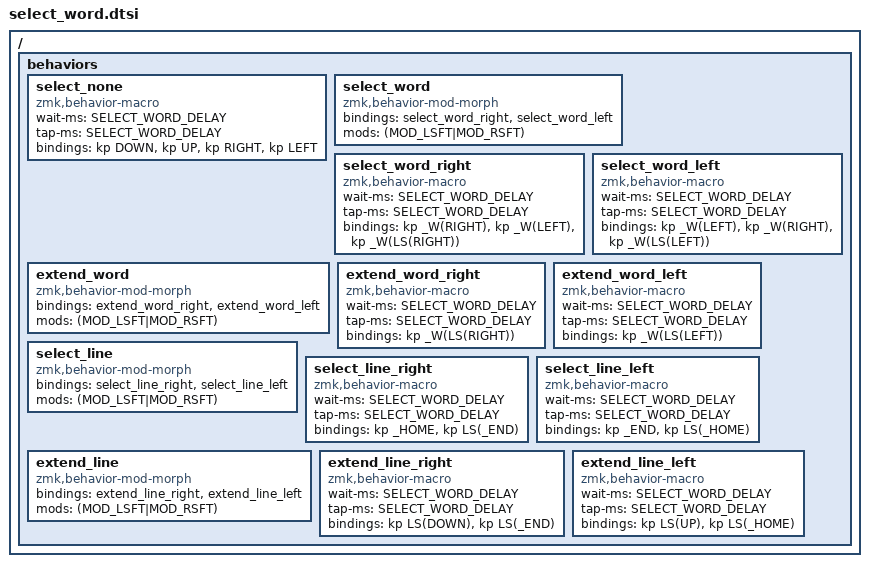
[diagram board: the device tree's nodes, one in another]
/* Original code copied from Sunaku's Keymap modified to use zmk-helpers - https://github.com/sunaku/glove80-keymaps */

/* Include helpers here as they are required for the behavior.

   NOTE: all usages of ZMK_ functions are overriden from this point on,
   so only include modules/functions working with them
*/
#include <zmk-helpers/helper.h>

/* Include the shortcuts.h if not included yet */
#ifndef _ZMK_KEYMAP_UTILS_SHORTCUTS_IMPORT
#include <zmk-keymap-utils/shortcuts.h>
#endif

//////////////////////////////////////////////////////////////////////////
//
// Approximation of Pascal Getreuer's Select Word macro from QMK
// - https://getreuer.info/posts/keyboards/select-word/index.html
//
//////////////////////////////////////////////////////////////////////////

//
// SELECT_WORD_DELAY defines how long the macro waits (milliseconds)
// after moving the cursor before it selects a word.  A larger delay
// may allow the macro to move to the next word upon each invocation.
//
#ifndef SELECT_WORD_DELAY
#define SELECT_WORD_DELAY 1
#endif

//////////////////////////////////////////////////////////////////////////
//
// Approximation of Pascal Getreuer's Select Word macro from QMK
// - https://getreuer.info/posts/keyboards/select-word/index.html
//
//////////////////////////////////////////////////////////////////////////

//
// SELECT_WORD_DELAY defines how long the macro waits (milliseconds)
// after moving the cursor before it selects a word.  A larger delay
// may allow the macro to move to the next word upon each invocation.
//
#ifndef SELECT_WORD_DELAY
#define SELECT_WORD_DELAY 1
#endif

// select all alias for shortcut
#define select_all kp _C(A)

ZMK_MACRO(select_none,
    wait-ms = <SELECT_WORD_DELAY>;
    tap-ms = <SELECT_WORD_DELAY>;
    bindings = <&kp DOWN &kp UP &kp RIGHT &kp LEFT>;
)

//
// select a word (jumps to next word upon each successive invocation)
//
ZMK_MOD_MORPH(select_word,
    bindings = <&select_word_right>, <&select_word_left>;
    mods = <(MOD_LSFT|MOD_RSFT)>;
)
ZMK_MACRO(select_word_right,
    wait-ms = <SELECT_WORD_DELAY>;
    tap-ms = <SELECT_WORD_DELAY>;
    bindings = <&kp _W(RIGHT) &kp _W(LEFT) &kp _W(LS(RIGHT))>;
)
ZMK_MACRO(select_word_left,
    wait-ms = <SELECT_WORD_DELAY>;
    tap-ms = <SELECT_WORD_DELAY>;
    bindings = <&kp _W(LEFT) &kp _W(RIGHT) &kp _W(LS(LEFT))>;
)
//
// extend current selection by one word
//
ZMK_MOD_MORPH(extend_word,
    bindings = <&extend_word_right>, <&extend_word_left>;
    mods = <(MOD_LSFT|MOD_RSFT)>;
)
ZMK_MACRO(extend_word_right,
    wait-ms = <SELECT_WORD_DELAY>;
    tap-ms = <SELECT_WORD_DELAY>;
    bindings = <&kp _W(LS(RIGHT))>;
)
ZMK_MACRO(extend_word_left,
    wait-ms = <SELECT_WORD_DELAY>;
    tap-ms = <SELECT_WORD_DELAY>;
    bindings = <&kp _W(LS(LEFT))>;
)

//
// select current line
//
ZMK_MOD_MORPH(select_line,
    bindings = <&select_line_right>, <&select_line_left>;
    mods = <(MOD_LSFT|MOD_RSFT)>;
)
ZMK_MACRO(select_line_right,
    wait-ms = <SELECT_WORD_DELAY>;
    tap-ms = <SELECT_WORD_DELAY>;
    bindings = <&kp _HOME &kp LS(_END)>;
)
ZMK_MACRO(select_line_left,
    wait-ms = <SELECT_WORD_DELAY>;
    tap-ms = <SELECT_WORD_DELAY>;
    bindings = <&kp _END &kp LS(_HOME)>;
)

//
// extend current selection by one line
//
ZMK_MOD_MORPH(extend_line,
    bindings = <&extend_line_right>, <&extend_line_left>;
    mods = <(MOD_LSFT|MOD_RSFT)>;
)
ZMK_MACRO(extend_line_right,
    wait-ms = <SELECT_WORD_DELAY>;
    tap-ms = <SELECT_WORD_DELAY>;
    bindings = <&kp LS(DOWN) &kp LS(_END)>;
)
ZMK_MACRO(extend_line_left,
    wait-ms = <SELECT_WORD_DELAY>;
    tap-ms = <SELECT_WORD_DELAY>;
    bindings = <&kp LS(UP) &kp LS(_HOME)>;
)
